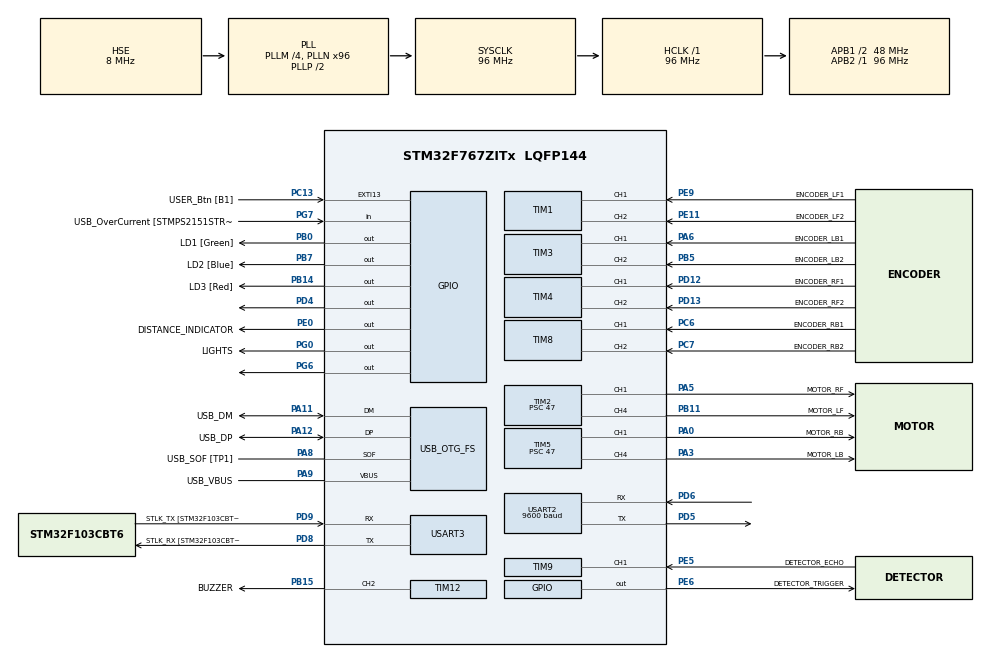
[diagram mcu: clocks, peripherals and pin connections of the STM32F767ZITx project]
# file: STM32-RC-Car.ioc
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Dma.Request0=USART2_RX
Dma.Request1=USART2_TX
Dma.USART2_RX.0.Direction=DMA_PERIPH_TO_MEMORY
Dma.USART2_RX.0.FIFOMode=DMA_FIFOMODE_DISABLE
Dma.USART2_RX.0.Instance=DMA1_Stream5
Dma.USART2_RX.0.MemDataAlignment=DMA_MDATAALIGN_BYTE
Dma.USART2_RX.0.MemInc=DMA_MINC_ENABLE
Dma.USART2_RX.0.Mode=DMA_NORMAL
Dma.USART2_RX.0.PeriphDataAlignment=DMA_PDATAALIGN_BYTE
Dma.USART2_RX.0.PeriphInc=DMA_PINC_DISABLE
Dma.USART2_RX.0.Priority=DMA_PRIORITY_LOW
Dma.USART2_TX.1.Direction=DMA_MEMORY_TO_PERIPH
Dma.USART2_TX.1.FIFOMode=DMA_FIFOMODE_DISABLE
Dma.USART2_TX.1.Instance=DMA1_Stream6
Dma.USART2_TX.1.MemDataAlignment=DMA_MDATAALIGN_BYTE
Dma.USART2_TX.1.MemInc=DMA_MINC_ENABLE
Dma.USART2_TX.1.Mode=DMA_NORMAL
Dma.USART2_TX.1.PeriphDataAlignment=DMA_PDATAALIGN_BYTE
Dma.USART2_TX.1.PeriphInc=DMA_PINC_DISABLE
Dma.USART2_TX.1.Priority=DMA_PRIORITY_LOW
FREERTOS.Tasks01=defaultTask,24,128,StartDefaultTask,Default,NULL,Dynamic,NULL,NULL
Mcu.Family=STM32F7
Mcu.Name=STM32F767ZITx
Mcu.Package=LQFP144
NVIC.DMA1_Stream5_IRQn=true\:5\:0\:false\:false\:true\:true\:false\:true\:true
NVIC.DMA1_Stream6_IRQn=true\:5\:0\:false\:false\:true\:true\:false\:true\:true
NVIC.EXTI15_10_IRQn=true\:5\:0\:false\:false\:true\:true\:true\:true\:true
NVIC.PriorityGroup=NVIC_PRIORITYGROUP_4
NVIC.TIM1_BRK_TIM9_IRQn=true\:5\:0\:false\:false\:true\:true\:true\:true\:true
NVIC.TIM1_CC_IRQn=true\:5\:0\:false\:false\:true\:true\:true\:true\:true
NVIC.TIM1_TRG_COM_TIM11_IRQn=true\:5\:0\:false\:false\:true\:true\:true\:true\:true
NVIC.TIM1_UP_TIM10_IRQn=true\:5\:0\:false\:false\:true\:true\:true\:true\:true
NVIC.TIM2_IRQn=true\:5\:0\:false\:false\:true\:true\:true\:true\:true
NVIC.TIM3_IRQn=true\:5\:0\:false\:false\:true\:true\:true\:true\:true
NVIC.TIM4_IRQn=true\:5\:0\:false\:false\:true\:true\:true\:true\:true
NVIC.TIM5_IRQn=true\:5\:0\:false\:false\:true\:true\:true\:true\:true
NVIC.TIM6_DAC_IRQn=true\:5\:0\:false\:false\:true\:true\:true\:true\:true
NVIC.TIM8_BRK_TIM12_IRQn=true\:5\:0\:false\:false\:true\:true\:true\:true\:true
NVIC.TIM8_CC_IRQn=true\:5\:0\:false\:false\:true\:true\:true\:true\:true
NVIC.TIM8_TRG_COM_TIM14_IRQn=true\:5\:0\:false\:false\:true\:true\:true\:true\:true
NVIC.TIM8_UP_TIM13_IRQn=true\:5\:0\:false\:false\:true\:true\:true\:true\:true
NVIC.USART2_IRQn=true\:5\:0\:false\:false\:true\:true\:true\:true\:true
NVIC.USART3_IRQn=true\:5\:0\:false\:false\:true\:true\:true\:true\:true
NimaLTD.I-CUBE-ATC.4.2.2.DriverJjATC=true
PA0/WKUP.GPIO_Label=MOTOR_RB
PA0/WKUP.Signal=S_TIM5_CH1
PA1.Signal=ETH_REF_CLK
PA10.GPIO_Label=USB_ID
PA10.Signal=USB_OTG_FS_ID
PA11.GPIO_Label=USB_DM
PA11.Mode=Device_Only
PA11.Signal=USB_OTG_FS_DM
PA12.GPIO_Label=USB_DP
PA12.Mode=Device_Only
PA12.Signal=USB_OTG_FS_DP
PA13.GPIO_Label=TMS
PA13.Mode=Serial_Wire
PA13.Signal=SYS_JTMS-SWDIO
PA14.GPIO_Label=TCK
PA14.Mode=Serial_Wire
PA14.Signal=SYS_JTCK-SWCLK
PA2.GPIO_Label=RMII_MDIO [LAN8742A-CZ-TR_MDIO]
PA2.Signal=ETH_MDIO
PA3.GPIO_Label=MOTOR_LB
PA3.Signal=S_TIM5_CH4
PA5.GPIO_Label=MOTOR_RF
PA5.Signal=S_TIM2_CH1_ETR
PA6.GPIO_Label=ENCODER_LB1
PA6.Signal=S_TIM3_CH1
PA7.GPIO_Label=RMII_CRS_DV [LAN8742A-CZ-TR_CRS_DV]
PA7.Signal=ETH_CRS_DV
PA8.GPIO_Label=USB_SOF [TP1]
PA8.Mode=Activate_SOF_FS
PA8.Signal=USB_OTG_FS_SOF
PA9.GPIO_Label=USB_VBUS
PA9.Mode=Activate_VBUS
PA9.Signal=USB_OTG_FS_VBUS
PB0.GPIO_Label=LD1 [Green]
PB0.Signal=GPIO_Output
PB11.GPIO_Label=MOTOR_LF
PB11.Signal=S_TIM2_CH4
PB13.GPIO_Label=RMII_TXD1 [LAN8742A-CZ-TR_TXD1]
PB13.Signal=ETH_TXD1
PB14.GPIO_Label=LD3 [Red]
PB14.Signal=GPIO_Output
PB15.GPIO_Label=BUZZER
PB15.Signal=S_TIM12_CH2
PB3.GPIO_Label=SWO
PB3.Signal=SYS_JTDO-SWO
PB5.GPIO_Label=ENCODER_LB2
PB5.Signal=S_TIM3_CH2
PB7.GPIO_Label=LD2 [Blue]
PB7.Signal=GPIO_Output
PC1.GPIO_Label=RMII_MDC [LAN8742A-CZ-TR_MDC]
PC1.Signal=ETH_MDC
PC13.GPIO_Label=USER_Btn [B1]
PC13.GPIO_ModeDefaultEXTI=GPIO_MODE_IT_FALLING
PC13.Signal=GPXTI13
PC14/OSC32_IN.Mode=LSE-External-Oscillator
PC14/OSC32_IN.Signal=RCC_OSC32_IN
PC15/OSC32_OUT.Mode=LSE-External-Oscillator
PC15/OSC32_OUT.Signal=RCC_OSC32_OUT
PC4.GPIO_Label=RMII_RXD0 [LAN8742A-CZ-TR_RXD0]
PC4.Signal=ETH_RXD0
PC5.GPIO_Label=RMII_RXD1 [LAN8742A-CZ-TR_RXD1]
PC5.Signal=ETH_RXD1
PC6.GPIO_Label=ENCODER_RB1
PC6.Signal=S_TIM8_CH1
PC7.GPIO_Label=ENCODER_RB2
PC7.Signal=S_TIM8_CH2
PD12.GPIO_Label=ENCODER_RF1
PD12.Signal=S_TIM4_CH1
PD13.GPIO_Label=ENCODER_RF2
PD13.Signal=S_TIM4_CH2
PD4.Signal=GPIO_Output
PD5.Mode=Asynchronous
PD5.Signal=USART2_TX
PD6.Mode=Asynchronous
PD6.Signal=USART2_RX
PD8.GPIO_Label=STLK_RX [STM32F103CBT6_PA3]
PD8.Mode=Asynchronous
PD8.Signal=USART3_TX
PD9.GPIO_Label=STLK_TX [STM32F103CBT6_PA2]
PD9.Mode=Asynchronous
PD9.Signal=USART3_RX
PE0.GPIO_Label=DISTANCE_INDICATOR
PE0.Signal=GPIO_Output
PE11.GPIO_Label=ENCODER_LF2
PE11.Signal=S_TIM1_CH2
PE5.GPIO_Label=DETECTOR_ECHO
PE5.Signal=S_TIM9_CH1
PE6.GPIO_Label=DETECTOR_TRIGGER
PE6.Signal=GPIO_Output
PE9.GPIO_Label=ENCODER_LF1
PE9.Signal=S_TIM1_CH1
PG0.GPIO_Label=LIGHTS
PG0.Signal=GPIO_Output
PG11.GPIO_Label=RMII_TX_EN [LAN8742A-CZ-TR_TXEN]
PG11.Signal=ETH_TX_EN
PG13.GPIO_Label=RMII_TXD0 [LAN8742A-CZ-TR_TXD0]
PG13.Signal=ETH_TXD0
PG6.Signal=GPIO_Output
PG7.GPIO_Label=USB_OverCurrent [STMPS2151STR_FAULT]
PG7.Signal=GPIO_Input
PH0/OSC_IN.GPIO_Label=MCO [STM32F103CBT6_PA8]
PH0/OSC_IN.Mode=HSE-External-Oscillator
PH0/OSC_IN.Signal=RCC_OSC_IN
PH1/OSC_OUT.Mode=HSE-External-Oscillator
PH1/OSC_OUT.Signal=RCC_OSC_OUT
ProjectManager.HeapSize=0x200
ProjectManager.StackSize=0x400
ProjectManager.TargetToolchain=STM32CubeIDE
RCC.48MHZClocksFreq_Value=24000000
RCC.AHBFreq_Value=96000000
RCC.APB1CLKDivider=RCC_HCLK_DIV2
RCC.APB1Freq_Value=48000000
RCC.APB1TimFreq_Value=96000000
RCC.APB2Freq_Value=96000000
RCC.APB2TimFreq_Value=96000000
RCC.CortexFreq_Value=96000000
RCC.HCLKFreq_Value=96000000
RCC.HSE_VALUE=8000000
RCC.HSI_VALUE=16000000
RCC.PLLM=4
RCC.PLLMUL=RCC_PLL_MUL9
RCC.PLLN=96
RCC.PLLQ=4
RCC.PRESCALERUSB=RCC_USBCLKSOURCE_PLL_DIV1_5
RCC.SYSCLKFreq_VALUE=96000000
RCC.SYSCLKSource=RCC_SYSCLKSOURCE_PLLCLK
RCC.SYSCLKSourceVirtual=RCC_SYSCLKSOURCE_PLLCLK
RCC.USBFreq_Value=48000000
RCC.VCOOutputFreq_Value=192000000
SH.S_TIM12_CH2.0=TIM12_CH2,PWM Generation2 CH2
SH.S_TIM1_CH1.0=TIM1_CH1,Encoder_Interface
SH.S_TIM1_CH2.0=TIM1_CH2,Encoder_Interface
SH.S_TIM2_CH1_ETR.0=TIM2_CH1,PWM Generation1 CH1
SH.S_TIM2_CH4.0=TIM2_CH4,PWM Generation4 CH4
SH.S_TIM3_CH1.0=TIM3_CH1,Encoder_Interface
SH.S_TIM3_CH2.0=TIM3_CH2,Encoder_Interface
SH.S_TIM4_CH1.0=TIM4_CH1,Encoder_Interface
SH.S_TIM4_CH2.0=TIM4_CH2,Encoder_Interface
SH.S_TIM5_CH1.0=TIM5_CH1,PWM Generation1 CH1
SH.S_TIM5_CH4.0=TIM5_CH4,PWM Generation4 CH4
SH.S_TIM8_CH1.0=TIM8_CH1,Encoder_Interface
SH.S_TIM8_CH2.0=TIM8_CH2,Encoder_Interface
SH.S_TIM9_CH1.0=TIM9_CH1,Input_Capture1_from_TI1
TIM1.CounterMode=TIM_COUNTERMODE_DOWN
TIM1.EncoderMode=TIM_ENCODERMODE_TI12
TIM1.IC1Filter=15
TIM1.IC1Polarity=TIM_ICPOLARITY_RISING
TIM1.IC2Filter=15
TIM1.IC2Polarity=TIM_ICPOLARITY_RISING
TIM12.Channel-PWM\ Generation2\ CH2=TIM_CHANNEL_2
TIM12.Period=999
TIM12.Prescaler=95
TIM2.Channel-PWM\ Generation1\ CH1=TIM_CHANNEL_1
TIM2.Channel-PWM\ Generation4\ CH4=TIM_CHANNEL_4
TIM2.Period=999
TIM2.Prescaler=47
TIM3.CounterMode=TIM_COUNTERMODE_DOWN
TIM3.EncoderMode=TIM_ENCODERMODE_TI12
TIM3.IC1Filter=15
TIM3.IC1Polarity=TIM_ICPOLARITY_RISING
TIM3.IC2Filter=15
TIM3.IC2Polarity=TIM_ICPOLARITY_RISING
TIM4.CounterMode=TIM_COUNTERMODE_DOWN
TIM4.EncoderMode=TIM_ENCODERMODE_TI12
TIM4.IC1Filter=15
TIM4.IC1Polarity=TIM_ICPOLARITY_RISING
TIM4.IC2Filter=15
TIM4.IC2Polarity=TIM_ICPOLARITY_RISING
TIM5.Channel-PWM\ Generation1\ CH1=TIM_CHANNEL_1
TIM5.Channel-PWM\ Generation4\ CH4=TIM_CHANNEL_4
TIM5.Period=999
TIM5.Prescaler=47
TIM6.Period=999
TIM6.Prescaler=9599
TIM8.CounterMode=TIM_COUNTERMODE_DOWN
TIM8.EncoderMode=TIM_ENCODERMODE_TI12
TIM8.IC1Filter=15
TIM8.IC1Polarity=TIM_ICPOLARITY_RISING
TIM8.IC2Filter=15
TIM8.IC2Polarity=TIM_ICPOLARITY_RISING
TIM9.Channel-Input_Capture1_from_TI1=TIM_CHANNEL_1
TIM9.Prescaler=95
USART2.BaudRate=9600
USART2.VirtualMode-Asynchronous=VM_ASYNC
USART3.VirtualMode-Asynchronous=VM_ASYNC
USB_OTG_FS.VirtualMode=Device_Only
VP_FREERTOS_VS_CMSIS_V2.Mode=CMSIS_V2
VP_NimaLTD.I-CUBE-ATC_VS_DriverJjATC_1.0.0_4.2.2.Mode=DriverJjATC
VP_TIM6_VS_ClockSourceINT.Mode=Enable_Timer
VP_TIM9_VS_ClockSourceINT.Mode=Internal
board=NUCLEO-F767ZI

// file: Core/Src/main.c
/* USER CODE BEGIN Header */
/**
  ******************************************************************************
  * @file           : main.c
  * @brief          : Main program body
  ******************************************************************************
  * @attention
  *
  * Copyright (c) 2025 STMicroelectronics.
  * All rights reserved.
  *
  * This software is licensed under terms that can be found in the LICENSE file
  * in the root directory of this software component.
  * If no LICENSE file comes with this software, it is provided AS-IS.
  *
  ******************************************************************************
  */
/* USER CODE END Header */
#include "main.h"

/* USER CODE BEGIN Includes */
#include "motor.h"
#include "string.h"
/* USER CODE END Includes */

void SystemClock_Config(void);
void MX_FREERTOS_Init(void);

/* USER CODE BEGIN 0 */

/*=================================*/

/* USER CODE END 0 */

int main(void)
{

  /* MCU Configuration--------------------------------------------------------*/

  /* Reset of all peripherals, Initializes the Flash interface and the Systick. */
  HAL_Init();

  /* Configure the system clock */
  SystemClock_Config();

  /* Initialize all configured peripherals */
  MX_GPIO_Init();
  MX_DMA_Init();
  MX_USART3_UART_Init();
  MX_USB_OTG_FS_PCD_Init();
  MX_USART2_UART_Init();
  MX_TIM1_Init();
  MX_TIM3_Init();
  MX_TIM4_Init();
  MX_TIM8_Init();
  MX_TIM2_Init();
  MX_TIM6_Init();
  MX_TIM5_Init();
  MX_TIM12_Init();
  MX_TIM9_Init();
  /* USER CODE BEGIN 2 */

  const char *readyMsg = "STM32 ready to receive data from HC05...\r\n";
  HAL_UART_Transmit(&huart3, (uint8_t *)readyMsg, strlen(readyMsg), HAL_MAX_DELAY);
  HAL_UART_Receive_IT(&huart2, &rxData, 1);

  Init_MotorSystem();

  //Set_PWM_Frequency(1000); // BUZZER

  /* USER CODE END 2 */

  /* Init scheduler */
  osKernelInitialize();

  /* Call init function for freertos objects (in cmsis_os2.c) */
  MX_FREERTOS_Init();

  /* Start scheduler */
  osKernelStart();

  /* We should never get here as control is now taken by the scheduler */

  /* Infinite loop */
  while (1)
  {

  }
}

void SystemClock_Config(void)
{
  RCC_OscInitTypeDef RCC_OscInitStruct = {0};
  RCC_ClkInitTypeDef RCC_ClkInitStruct = {0};

  /** Configure LSE Drive Capability
  */
  HAL_PWR_EnableBkUpAccess();

  /** Configure the main internal regulator output voltage
  */
  __HAL_RCC_PWR_CLK_ENABLE();
  __HAL_PWR_VOLTAGESCALING_CONFIG(PWR_REGULATOR_VOLTAGE_SCALE3);

  /** Initializes the RCC Oscillators according to the specified parameters
  * in the RCC_OscInitTypeDef structure.
  */
  RCC_OscInitStruct.OscillatorType = RCC_OSCILLATORTYPE_HSE;
  RCC_OscInitStruct.HSEState = RCC_HSE_ON;
  RCC_OscInitStruct.PLL.PLLState = RCC_PLL_ON;
  RCC_OscInitStruct.PLL.PLLSource = RCC_PLLSOURCE_HSE;
  RCC_OscInitStruct.PLL.PLLM = 4;
  RCC_OscInitStruct.PLL.PLLN = 96;
  RCC_OscInitStruct.PLL.PLLP = RCC_PLLP_DIV2;
  RCC_OscInitStruct.PLL.PLLQ = 4;
  RCC_OscInitStruct.PLL.PLLR = 2;
  if (HAL_RCC_OscConfig(&RCC_OscInitStruct) != HAL_OK)
  {
    Error_Handler();
  }

  /** Activate the Over-Drive mode
  */
  if (HAL_PWREx_EnableOverDrive() != HAL_OK)
  {
    Error_Handler();
  }

  /** Initializes the CPU, AHB and APB buses clocks
  */
  RCC_ClkInitStruct.ClockType = RCC_CLOCKTYPE_HCLK|RCC_CLOCKTYPE_SYSCLK
                              |RCC_CLOCKTYPE_PCLK1|RCC_CLOCKTYPE_PCLK2;
  RCC_ClkInitStruct.SYSCLKSource = RCC_SYSCLKSOURCE_PLLCLK;
  RCC_ClkInitStruct.AHBCLKDivider = RCC_SYSCLK_DIV1;
  RCC_ClkInitStruct.APB1CLKDivider = RCC_HCLK_DIV2;
  RCC_ClkInitStruct.APB2CLKDivider = RCC_HCLK_DIV1;

  if (HAL_RCC_ClockConfig(&RCC_ClkInitStruct, FLASH_LATENCY_3) != HAL_OK)
  {
    Error_Handler();
  }
}

void Error_Handler(void)
{
  __disable_irq();
  while (1)
  {
  }
}

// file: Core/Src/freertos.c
/* USER CODE BEGIN Header */
/**
  ******************************************************************************
  * File Name          : freertos.c
  * Description        : Code for freertos applications
  ******************************************************************************
  * @attention
  *
  * Copyright (c) 2025 STMicroelectronics.
  * All rights reserved.
  *
  * This software is licensed under terms that can be found in the LICENSE file
  * in the root directory of this software component.
  * If no LICENSE file comes with this software, it is provided AS-IS.
  *
  ******************************************************************************
  */
/* USER CODE END Header */

#include "thread.h"

/* Definitions for defaultTask */

void StartDefaultTask(void *argument);

void MX_FREERTOS_Init(void); /* (MISRA C 2004 rule 8.1) */

void MX_FREERTOS_Init(void) {

  /* Create the thread(s) */
  /* creation of defaultTask */
	StartMultiThreads();

}

void StartDefaultTask(void *argument)
{
  for(;;)
  {
    osDelay(1);
  }
}
